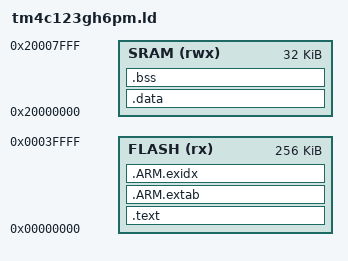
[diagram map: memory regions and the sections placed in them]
/******************************************************************************
 *
 * project.ld - Linker configuration file for project.
 *
 * Copyright (c) 2013-2017 Texas Instruments Incorporated.  All rights reserved.
 * Software License Agreement
 *
 *   Redistribution and use in source and binary forms, with or without
 *   modification, are permitted provided that the following conditions
 *   are met:
 *
 *   Redistributions of source code must retain the above copyright
 *   notice, this list of conditions and the following disclaimer.
 *
 *   Redistributions in binary form must reproduce the above copyright
 *   notice, this list of conditions and the following disclaimer in the
 *   documentation and/or other materials provided with the
 *   distribution.
 *
 *   Neither the name of Texas Instruments Incorporated nor the names of
 *   its contributors may be used to endorse or promote products derived
 *   from this software without specific prior written permission.
 *
 * THIS SOFTWARE IS PROVIDED BY THE COPYRIGHT HOLDERS AND CONTRIBUTORS
 * "AS IS" AND ANY EXPRESS OR IMPLIED WARRANTIES, INCLUDING, BUT NOT
 * LIMITED TO, THE IMPLIED WARRANTIES OF MERCHANTABILITY AND FITNESS FOR
 * A PARTICULAR PURPOSE ARE DISCLAIMED. IN NO EVENT SHALL THE COPYRIGHT
 * OWNER OR CONTRIBUTORS BE LIABLE FOR ANY DIRECT, INDIRECT, INCIDENTAL,
 * SPECIAL, EXEMPLARY, OR CONSEQUENTIAL DAMAGES (INCLUDING, BUT NOT
 * LIMITED TO, PROCUREMENT OF SUBSTITUTE GOODS OR SERVICES; LOSS OF USE,
 * DATA, OR PROFITS; OR BUSINESS INTERRUPTION) HOWEVER CAUSED AND ON ANY
 * THEORY OF LIABILITY, WHETHER IN CONTRACT, STRICT LIABILITY, OR TORT
 * (INCLUDING NEGLIGENCE OR OTHERWISE) ARISING IN ANY WAY OUT OF THE USE
 * OF THIS SOFTWARE, EVEN IF ADVISED OF THE POSSIBILITY OF SUCH DAMAGE.
 *
 * This is part of revision 2.1.4.178 of the Tiva Firmware Development Package.
 *
 *****************************************************************************/

MEMORY
{
    FLASH (rx) : ORIGIN = 0x00000000, LENGTH = 0x00040000
    SRAM (rwx) : ORIGIN = 0x20000000, LENGTH = 0x00008000
}

/* references:
 * - http://infocenter.arm.com/help/topic/com.arm.doc.ihi0044f/IHI0044F_aaelf.pdf
 * - https://en.wikipedia.org/wiki/Executable_and_Linkable_Format
 * - http://blogs.bu.edu/md/2011/11/15/the-dark-art-of-linker-scripts/
 * - https://stackoverflow.com/questions/45393551/gnu-linker-arm-why-my-sections-overlap
 * - http://www.hertaville.com/a-sample-linker-script.html
 * - https://patchwork.ozlabs.org/patch/511396/
 * - https://github.com/bjornfor/stm32-test/blob/master/stm32.ld
 */

SECTIONS
{
    .text :
    {
        _text = .;
        KEEP(*(.isr_vector))
        *(.text*)
        *(.rodata*)
	/* Static constructors and destructors */
	KEEP (*(.init))
	KEEP (*(.fini))
        _etext = .;
    } > FLASH

    /* Stack unwinding and exception handling sections.
     *
     * ARM compilers emit object files with .ARM.extab and .ARM.exidx sections
     * when using C++ exceptions. Also, at least GCC emits those sections when
     * dividing large numbers (64-bit) in C. So we have to handle them.
     *
     * (ARM uses .ARM.extab and .ARM.exidx instead of the .eh_frame section
     * used on x86.)
     */

    .ARM.extab : /* exception unwinding information */
    {
        *(.ARM.extab* .gnu.linkonce.armextab.*)
    } > FLASH

    .ARM.exidx : /* index entries for section unwinding */
    {
        *(.ARM.exidx* .gnu.linkonce.armexidx.*)
    } > FLASH

    .data : AT(ADDR(.text) + SIZEOF(.text))
    {
        _data = .;
        _ldata = LOADADDR (.data);
        *(vtable)
        *(.data*)
        _edata = .;
    } > SRAM

    .bss :
    {
        _bss = .;
        *(.bss*)
        *(COMMON)
        _ebss = .;
    } > SRAM
}
